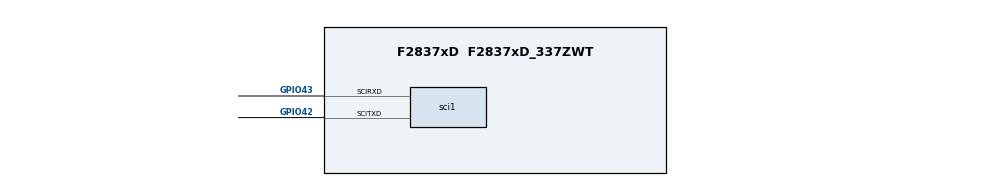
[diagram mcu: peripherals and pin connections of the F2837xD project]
/**
 * @cliArgs --board "/boards/LAUNCHXL_F28379D" --device "F2837xD" --part "F2837xD_337ZWT" --package "F2837xD_337ZWT" --context "CPU1" --product "C2000WARE@6.00.01.00"
 * @versions {"tool":"1.26.0+4407"}
 */

/**
 * Import the modules used in this configuration.
 */
const adc            = scripting.addModule("/driverlib/adc.js", {}, false);
const adc1           = adc.addInstance();
const adc2           = adc.addInstance();
const device_support = scripting.addModule("/driverlib/device_support.js");
const sci            = scripting.addModule("/driverlib/sci.js", {}, false);
const sci1           = sci.addInstance();

/**
 * Write custom configuration values to the imported modules.
 */
adc1.$name              = "myADCA";
adc1.adcClockPrescaler  = "ADC_CLK_DIV_4_0";
adc1.enabledSOCs        = ["ADC_SOC_NUMBER0"];
adc1.interruptPulseMode = "ADC_PULSE_END_OF_CONV";
adc1.enabledInts        = ["ADC_INT_NUMBER1"];
adc1.enableInterrupt1   = true;
adc1.adcResolutionMode  = "ADC_RESOLUTION_16BIT";
adc1.adcSignalMode      = "ADC_MODE_DIFFERENTIAL";
adc1.soc0Channel        = "ADC_CH_ADCIN0_ADCIN1";
adc1.soc0SampleWindow   = 200;

adc2.$name               = "myADCB";
adc2.adcBase             = "ADCB_BASE";
adc2.adcClockPrescaler   = "ADC_CLK_DIV_4_0";
adc2.enabledSOCs         = ["ADC_SOC_NUMBER0"];
adc2.soc0SampleWindow    = 200;
adc2.enabledInts         = ["ADC_INT_NUMBER1"];
adc2.interruptPulseMode  = "ADC_PULSE_END_OF_CONV";
adc2.enableInterrupt1    = true;
adc2.socHighPriorityMode = "ADC_PRI_ALL_HIPRI";
adc2.soc0Channel         = "ADC_CH_ADCIN2";

const divider3 = system.clockTree["EPWMCLKDIV"];
scripting.suppress("ePWM TZFRC and TZCLR events will sometimes be missed when EPWMCLKDIV is divide by 2\\. Always program EPWMCLKDIV to divide by 1 if using TZFRC or TZCLR register\\. Please refer to the F2837xD Silicon Errata for more details\\.", divider3, "EPWMCLK");

sci1.$name                 = "mySCI0";
sci1.enabledFIFOInterrupts = ["SCI_INT_RXFF","SCI_INT_TXFF"];
sci1.sci.scirxdPin.$assign = "GPIO43";
sci1.sci.scitxdPin.$assign = "GPIO42";
sci1.rxQual.$name          = "myGPIOQUAL0";
sci1.txQual.$name          = "myGPIOQUAL1";
sci1.txQual.qualMode       = "GPIO_QUAL_3SAMPLE";
scripting.suppress("Not pinned out,@@@.+?@@@ is not pinned out on the LaunchPad F28379D\\.  @@@.+?@@@", sci1.sci, "scirxdPin");
scripting.suppress("Not pinned out,@@@.+?@@@ is not pinned out on the LaunchPad F28379D\\.  @@@.+?@@@", sci1.sci, "scitxdPin");

/**
 * Pinmux solution for unlocked pins/peripherals. This ensures that minor changes to the automatic solver in a future
 * version of the tool will not impact the pinmux you originally saw.  These lines can be completely deleted in order to
 * re-solve from scratch.
 */
sci1.sci.$suggestSolution = "SCIA";
